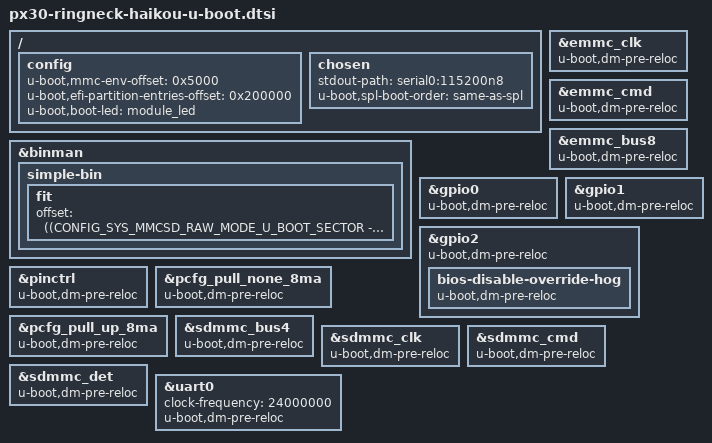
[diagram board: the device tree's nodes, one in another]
// SPDX-License-Identifier: GPL-2.0+

#include "px30-u-boot.dtsi"

/ {
	config {
		u-boot,mmc-env-offset = <0x5000>;      /* @  20KB */
		u-boot,efi-partition-entries-offset = <0x200000>; /* 2MB */
		u-boot,boot-led = "module_led";
	};

	chosen {
		stdout-path = "serial0:115200n8";
		u-boot,spl-boot-order = "same-as-spl", &emmc, &sdmmc;
	};
};

&binman {
	simple-bin {
		fit {
			offset = <((CONFIG_SYS_MMCSD_RAW_MODE_U_BOOT_SECTOR - 64) * 512)>;
		};
	};
};

&emmc_clk {
	u-boot,dm-pre-reloc;
};

&emmc_cmd {
	u-boot,dm-pre-reloc;
};

&emmc_bus8 {
	u-boot,dm-pre-reloc;
};

&gpio0 {
	u-boot,dm-pre-reloc;
};

&gpio1 {
	u-boot,dm-pre-reloc;
};

&gpio2 {
	u-boot,dm-pre-reloc;

	/*
	 * The Qseven BIOS_DISABLE signal on the PX30-µQ7 keeps the on-module
	 * eMMC powered-down initially (in fact it keeps the reset signal
	 * asserted). BIOS_DISABLE_OVERRIDE pin allows to re-enable eMMC after
	 * the SPL has been booted from SD Card.
	 */
	bios-disable-override-hog {
		u-boot,dm-pre-reloc;
	};
};

&pinctrl {
	u-boot,dm-pre-reloc;
};

&pcfg_pull_none_8ma {
	u-boot,dm-pre-reloc;
};

&pcfg_pull_up_8ma {
	u-boot,dm-pre-reloc;
};

&sdmmc_bus4 {
	u-boot,dm-pre-reloc;
};

&sdmmc_clk {
	u-boot,dm-pre-reloc;
};

&sdmmc_cmd {
	u-boot,dm-pre-reloc;
};

&sdmmc_det {
	u-boot,dm-pre-reloc;
};

&uart0 {
	clock-frequency = <24000000>;
	u-boot,dm-pre-reloc;
};
